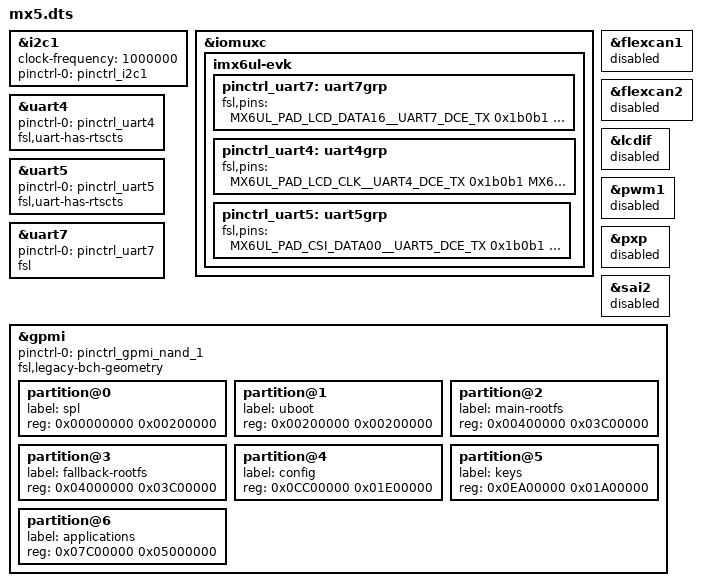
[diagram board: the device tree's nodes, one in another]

/*
 * Copyright (C) 2015-2016 Variscite Ltd. - http://www.variscite.com
 *
 * This program is free software; you can redistribute it and/or modify
 * it under the terms of the GNU General Public License version 2 as
 * published by the Free Software Foundation.
 */
/* SDCARD & NAND devices enabled eMMC & Wi-FI disabled.*/
/* #define WIFI */
/* #define EMMC */

/dts-v1/;

#define  NAND
#include "imx6ull.dtsi"

//Soup up the I2C interface to the XMEGA to 1MHz
&i2c1 {
        clock-frequency = <1000000>;
        pinctrl-names = "default";
        pinctrl-0 = <&pinctrl_i2c1>;
        status = "okay";
};

&iomuxc {
        imx6ul-evk {
                pinctrl_uart7: uart7grp {
                        fsl,pins = <
                                MX6UL_PAD_LCD_DATA16__UART7_DCE_TX      0x1b0b1
                                MX6UL_PAD_LCD_DATA17__UART7_DCE_RX      0x1b0b1
                        >;
                };

                /* UART to RS485 */
                pinctrl_uart4: uart4grp {       /* RX/TX RTS/CTS */
                        fsl,pins = <
                                MX6UL_PAD_LCD_CLK__UART4_DCE_TX         0x1b0b1
                                MX6UL_PAD_LCD_ENABLE__UART4_DCE_RX      0x1b0b1
                                MX6UL_PAD_LCD_HSYNC__UART4_DCE_CTS      0x1b0b1
                                MX6UL_PAD_LCD_VSYNC__UART4_DCE_RTS      0x1b0b1
                        >;
                };

                /* UART to RS485 */
                pinctrl_uart5: uart5grp {       /* RX/TX RTS/CTS */
                        fsl,pins = <
                                MX6UL_PAD_CSI_DATA00__UART5_DCE_TX      0x1b0b1
                                MX6UL_PAD_CSI_DATA01__UART5_DCE_RX      0x1b0b1
                                MX6UL_PAD_CSI_DATA03__UART5_DCE_CTS     0x1b0b1
                                MX6UL_PAD_CSI_DATA03__UART5_DTE_RTS     0x1b0b1
                        >;
                };

        };
};

/* UART to 2nd 485 interface */
&uart4 {
        pinctrl-names = "default";
        pinctrl-0 = <&pinctrl_uart4>;
        fsl,uart-has-rtscts;
        status = "okay";
};


/* UART to 1st 485 interface */
&uart5 {
        pinctrl-names = "default";
        pinctrl-0 = <&pinctrl_uart5>;
        fsl,uart-has-rtscts;
        status = "okay";
};



/* UART to xMEGA */
&uart7 {
        pinctrl-names = "default";
        pinctrl-0 = <&pinctrl_uart7>;
        fsl;
        status = "okay";
};

&flexcan1 {
        status = "disabled";
};

&flexcan2 {
        status = "disabled";
};

&lcdif {
        status = "disabled";
};

&pwm1 {
        status = "disabled";
};

&pxp {
        status = "disabled";
};

&sai2 {
        status = "disabled";
};


&gpmi {
    pinctrl-names = "default";
    pinctrl-0 = <&pinctrl_gpmi_nand_1>;
    fsl,legacy-bch-geometry;
    status = "okay";

    partition@0 {
        label = "spl";
        reg = <0x00000000 0x00200000>;
    };

    partition@1 {
        label = "uboot";
        reg = <0x00200000 0x00200000>;
    };
    partition@2 {

        label = "main-rootfs";
        reg = <0x00400000 0x03C00000>;
    };
        partition@3 {
        label = "fallback-rootfs";
         reg = <0x04000000 0x03C00000>;
    };
        partition@4 {
        label = "config";
        reg = <0x0CC00000 0x01E00000>;
    };
        partition@5 {
        label = "keys";
        reg = <0x0EA00000 0x01A00000>;    
    };

	partition@6 {
        label = "applications";
        reg = <0x07C00000 0x05000000>;
    };
};



